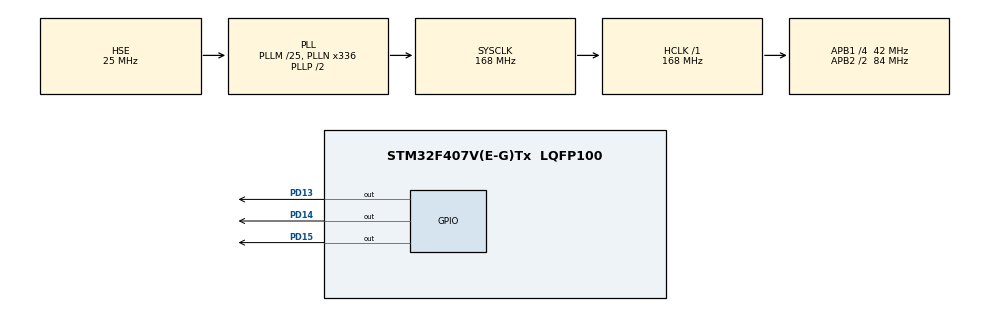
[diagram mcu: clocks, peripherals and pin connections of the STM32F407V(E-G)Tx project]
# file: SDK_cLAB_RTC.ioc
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IWDG.Prescaler=IWDG_PRESCALER_64
Mcu.Family=STM32F4
Mcu.Name=STM32F407V(E-G)Tx
Mcu.Package=LQFP100
NVIC.PriorityGroup=NVIC_PRIORITYGROUP_4
PA13.Mode=JTAG_5_pins
PA13.Signal=SYS_JTMS-SWDIO
PA14.Mode=JTAG_5_pins
PA14.Signal=SYS_JTCK-SWCLK
PA15.Mode=JTAG_5_pins
PA15.Signal=SYS_JTDI
PB3.Mode=JTAG_5_pins
PB3.Signal=SYS_JTDO-SWO
PB4.Mode=JTAG_5_pins
PB4.Signal=SYS_JTRST
PC14-OSC32_IN.Mode=LSE-External-Oscillator
PC14-OSC32_IN.Signal=RCC_OSC32_IN
PC15-OSC32_OUT.Mode=LSE-External-Oscillator
PC15-OSC32_OUT.Signal=RCC_OSC32_OUT
PD13.GPIO_Speed=GPIO_SPEED_FREQ_HIGH
PD13.PinState=GPIO_PIN_RESET
PD13.Signal=GPIO_Output
PD14.GPIO_Speed=GPIO_SPEED_FREQ_HIGH
PD14.PinState=GPIO_PIN_RESET
PD14.Signal=GPIO_Output
PD15.GPIO_Speed=GPIO_SPEED_FREQ_HIGH
PD15.Signal=GPIO_Output
PD5.Signal=USART2_TX
PD6.Signal=USART2_RX
PD8.Signal=USART3_TX
PD9.Signal=USART3_RX
PH0-OSC_IN.Mode=HSE-External-Oscillator
PH0-OSC_IN.Signal=RCC_OSC_IN
PH1-OSC_OUT.Mode=HSE-External-Oscillator
PH1-OSC_OUT.Signal=RCC_OSC_OUT
ProjectManager.HeapSize=0x200
ProjectManager.StackSize=0x400
ProjectManager.TargetToolchain=STM32CubeIDE
RCC.48MHZClocksFreq_Value=84000000
RCC.AHBFreq_Value=168000000
RCC.APB1CLKDivider=RCC_HCLK_DIV4
RCC.APB1Freq_Value=42000000
RCC.APB1TimFreq_Value=84000000
RCC.APB2CLKDivider=RCC_HCLK_DIV2
RCC.APB2Freq_Value=84000000
RCC.APB2TimFreq_Value=168000000
RCC.CortexFreq_Value=168000000
RCC.HCLKFreq_Value=168000000
RCC.HSE_VALUE=25000000
RCC.HSI_VALUE=16000000
RCC.PLLM=25
RCC.PLLN=336
RCC.PLLSourceVirtual=RCC_PLLSOURCE_HSE
RCC.RCC_RTC_Clock_Source=RCC_RTCCLKSOURCE_LSI
RCC.RCC_RTC_Clock_SourceVirtual=RCC_RTCCLKSOURCE_LSE
RCC.SYSCLKFreq_VALUE=168000000
RCC.SYSCLKSource=RCC_SYSCLKSOURCE_PLLCLK
RCC.VCOOutputFreq_Value=336000000
RTC.Hours=16
RTC.Minutes=20
RTC.Seconds=30
VP_IWDG_VS_IWDG.Mode=IWDG_Activate
VP_RTC_VS_RTC_Activate.Mode=RTC_Enabled
VP_RTC_VS_RTC_Calendar.Mode=RTC_Calendar
board=custom

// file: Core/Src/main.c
/* USER CODE BEGIN Header */
/**
  ******************************************************************************
  * @file           : main.c
  * @brief          : Main program body
  ******************************************************************************
  * @attention
  *
  * <h2><center>&copy; Copyright (c) 2020 STMicroelectronics.
  * All rights reserved.</center></h2>
  *
  * This software component is licensed by ST under BSD 3-Clause license,
  * the "License"; You may not use this file except in compliance with the
  * License. You may obtain a copy of the License at:
  *                        opensource.org/licenses/BSD-3-Clause
  *
  ******************************************************************************
  */
/* USER CODE END Header */
#include "main.h"
#include "iwdg.h"
#include "rtc.h"
#include "gpio.h"

/* USER CODE BEGIN Includes */
#include "trace.h"
#include "stdio.h"
/* USER CODE END Includes */

/* USER CODE BEGIN PV */
const char buf[17] = "";
/* USER CODE END PV */

void SystemClock_Config(void);

int main(void)
{

  /* MCU Configuration--------------------------------------------------------*/

  /* Reset of all peripherals, Initializes the Flash interface and the Systick. */
  HAL_Init();

  /* Configure the system clock */
  SystemClock_Config();

  /* Initialize all configured peripherals */
  MX_GPIO_Init();
  MX_IWDG_Init();
  MX_RTC_Init();
  /* USER CODE BEGIN 2 */

  /* Do not remove this code below */
  MX_TRACE_Init();
  SDK_TRACE_Start();
  /* Do not remove this code from above */

  /* Place your code from here */

  	RTC_TimeTypeDef time = {0};
	RTC_DateTypeDef date = {0};

	char str[100] = {0};

	HAL_RTC_GetTime(&hrtc, &time, RTC_FORMAT_BIN);
	HAL_RTC_GetDate(&hrtc, &date, RTC_FORMAT_BIN);

	SDK_TRACE_Timestamp(PRINT, 0);
  	SDK_TRACE_Timestamp(PRINT, 1);
	sprintf(str, "1: Hour = %d Minutes = %d Seconds = %d", time.Hours, time.Minutes, time.Seconds);
  	SDK_TRACE_Print(str);
  	SDK_TRACE_Timestamp(PRINT, 1);
	SDK_TRACE_Timestamp(PRINT, 0);

  	for(int i = 0; i < 100; i++)
  		str[i] = 0;

  	HAL_Delay(3000);

	HAL_RTC_GetTime(&hrtc, &time, RTC_FORMAT_BIN);
	HAL_RTC_GetDate(&hrtc, &date, RTC_FORMAT_BIN);

	SDK_TRACE_Timestamp(PRINT, 0);
  	SDK_TRACE_Timestamp(PRINT, 1);
	sprintf(str, "2: Hour = %d Minutes = %d Seconds = %d", time.Hours, time.Minutes, time.Seconds);
  	SDK_TRACE_Print(str);
  	SDK_TRACE_Timestamp(PRINT, 1);
	SDK_TRACE_Timestamp(PRINT, 0);

  /* Place your code before here */
  /* Do not remove this code below */
  SDK_TRACE_Stop();
  /* Do not remove this code from above */

  /* USER CODE END 2 */

  /* Infinite loop */
  while (1)
  {

  }
}

void SystemClock_Config(void)
{
  RCC_OscInitTypeDef RCC_OscInitStruct = {0};
  RCC_ClkInitTypeDef RCC_ClkInitStruct = {0};
  RCC_PeriphCLKInitTypeDef PeriphClkInitStruct = {0};

  /** Configure the main internal regulator output voltage
  */
  __HAL_RCC_PWR_CLK_ENABLE();
  __HAL_PWR_VOLTAGESCALING_CONFIG(PWR_REGULATOR_VOLTAGE_SCALE1);
  /** Initializes the RCC Oscillators according to the specified parameters
  * in the RCC_OscInitTypeDef structure.
  */
  RCC_OscInitStruct.OscillatorType = RCC_OSCILLATORTYPE_LSI|RCC_OSCILLATORTYPE_HSE;
  RCC_OscInitStruct.HSEState = RCC_HSE_ON;
  RCC_OscInitStruct.LSIState = RCC_LSI_ON;
  RCC_OscInitStruct.PLL.PLLState = RCC_PLL_ON;
  RCC_OscInitStruct.PLL.PLLSource = RCC_PLLSOURCE_HSE;
  RCC_OscInitStruct.PLL.PLLM = 25;
  RCC_OscInitStruct.PLL.PLLN = 336;
  RCC_OscInitStruct.PLL.PLLP = RCC_PLLP_DIV2;
  RCC_OscInitStruct.PLL.PLLQ = 4;
  if (HAL_RCC_OscConfig(&RCC_OscInitStruct) != HAL_OK)
  {
    Error_Handler();
  }
  /** Initializes the CPU, AHB and APB buses clocks
  */
  RCC_ClkInitStruct.ClockType = RCC_CLOCKTYPE_HCLK|RCC_CLOCKTYPE_SYSCLK
                              |RCC_CLOCKTYPE_PCLK1|RCC_CLOCKTYPE_PCLK2;
  RCC_ClkInitStruct.SYSCLKSource = RCC_SYSCLKSOURCE_PLLCLK;
  RCC_ClkInitStruct.AHBCLKDivider = RCC_SYSCLK_DIV1;
  RCC_ClkInitStruct.APB1CLKDivider = RCC_HCLK_DIV4;
  RCC_ClkInitStruct.APB2CLKDivider = RCC_HCLK_DIV2;

  if (HAL_RCC_ClockConfig(&RCC_ClkInitStruct, FLASH_LATENCY_5) != HAL_OK)
  {
    Error_Handler();
  }
  PeriphClkInitStruct.PeriphClockSelection = RCC_PERIPHCLK_RTC;
  PeriphClkInitStruct.RTCClockSelection = RCC_RTCCLKSOURCE_LSI;
  if (HAL_RCCEx_PeriphCLKConfig(&PeriphClkInitStruct) != HAL_OK)
  {
    Error_Handler();
  }
}

void Error_Handler(void)
{
}

/************************ (C) COPYRIGHT STMicroelectronics *****END OF FILE****/
